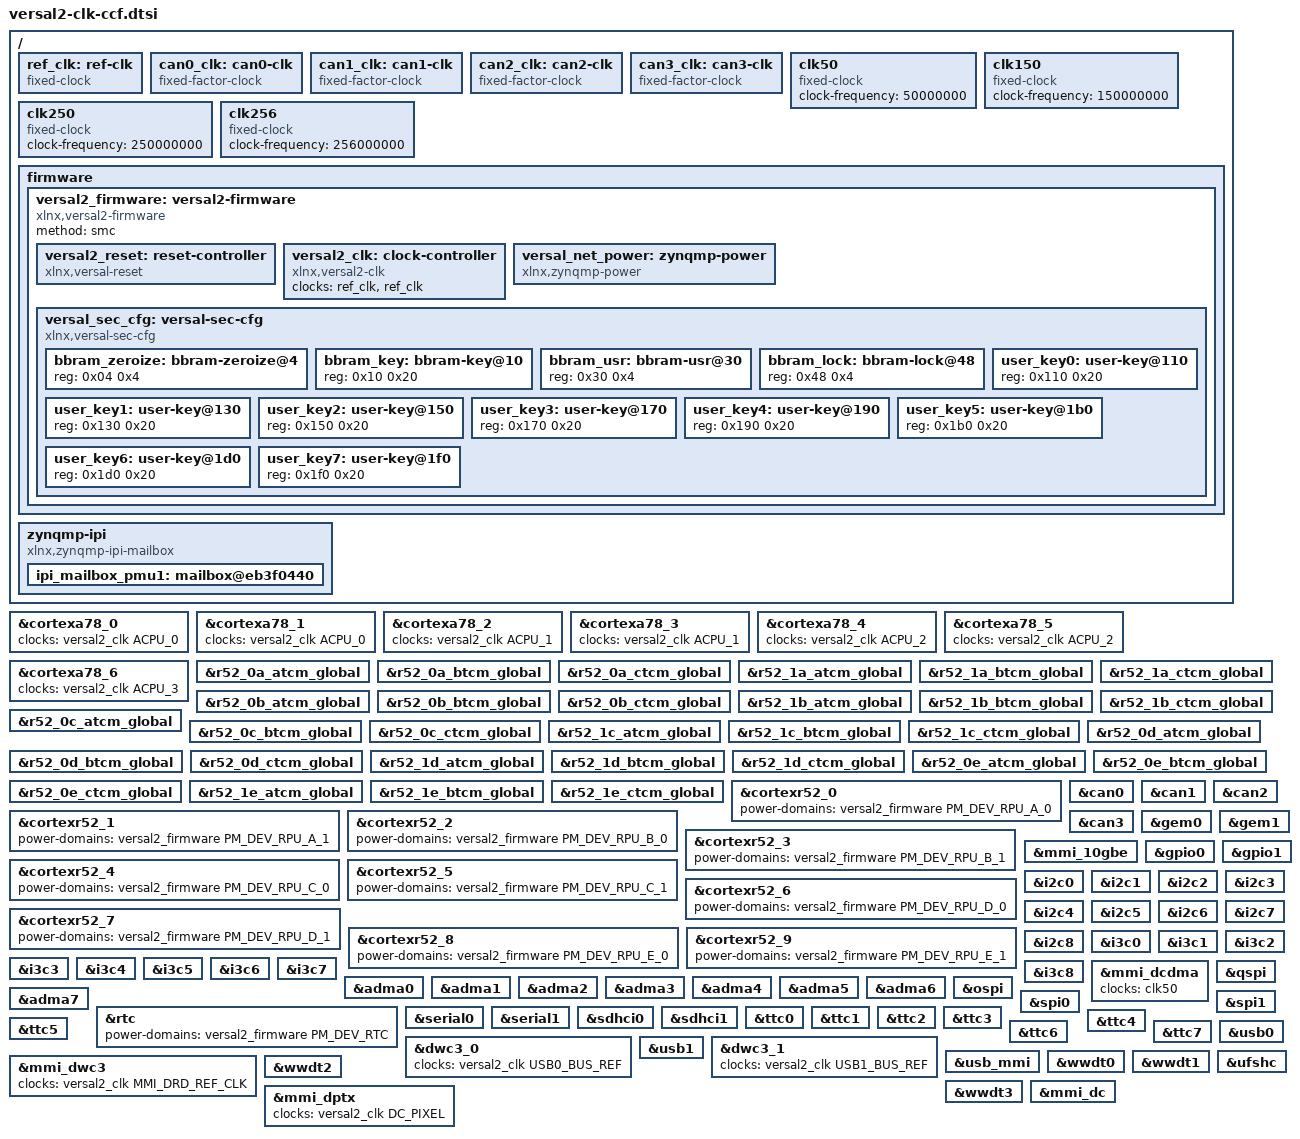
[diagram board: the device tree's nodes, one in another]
// SPDX-License-Identifier: GPL-2.0
/*
 * dts file for Xilinx Versal2 with PM
 *
 * Copyright (C) 2022, Xilinx, Inc.
 * Copyright (C) 2022 - 2025, Advanced Micro Devices, Inc.
 *
 * Michal Simek <michal.simek@amd.com>
 */

#include "include/dt-bindings/clock/xlnx-versal2-clk.h"
#include "include/dt-bindings/power/xlnx-versal2-power.h"
#include "include/dt-bindings/reset/xlnx-versal2-resets.h"

/ {
	ref_clk: ref-clk {
		bootph-all;
		compatible = "fixed-clock";
		#clock-cells = <0>;
		clock-frequency = <33333333>;
		clock-output-names = "ref_clk";
	};

	can0_clk: can0-clk {
		#clock-cells = <0>;
		compatible = "fixed-factor-clock";
		clocks = <&versal2_clk CAN0_REF_2X>;
		clock-div = <2>;
		clock-mult = <1>;
	};

	can1_clk: can1-clk {
		#clock-cells = <0>;
		compatible = "fixed-factor-clock";
		clocks = <&versal2_clk CAN1_REF_2X>;
		clock-div = <2>;
		clock-mult = <1>;
	};

	can2_clk: can2-clk {
		#clock-cells = <0>;
		compatible = "fixed-factor-clock";
		clocks = <&versal2_clk CAN2_REF_2X>;
		clock-div = <2>;
		clock-mult = <1>;
	};

	can3_clk: can3-clk {
		#clock-cells = <0>;
		compatible = "fixed-factor-clock";
		clocks = <&versal2_clk CAN3_REF_2X>;
		clock-div = <2>;
		clock-mult = <1>;
	};

	clk50: clk50 {
		compatible = "fixed-clock";
		#clock-cells = <0>;
		clock-frequency = <50000000>;
	};

	clk150: clk150 {
		compatible = "fixed-clock";
		#clock-cells = <0>;
		clock-frequency = <150000000>;
	};

	clk250: clk250 {
		compatible = "fixed-clock";
		#clock-cells = <0>;
		clock-frequency = <250000000>;
	};

	clk256: clk256 {
		compatible = "fixed-clock";
		#clock-cells = <0>;
		clock-frequency = <256000000>;
	};

	firmware {
		versal2_firmware: versal2-firmware {
			compatible = "xlnx,versal2-firmware";
			bootph-all;
			method = "smc";
			#power-domain-cells = <1>;

			versal2_reset: reset-controller {
				compatible = "xlnx,versal-reset";
				#reset-cells = <1>;
			};

			versal2_clk: clock-controller {
				#clock-cells = <1>;
				compatible = "xlnx,versal2-clk";
				bootph-all;
				clocks = <&ref_clk>, <&ref_clk>;
				clock-names = "ref", "pl_alt_ref";
			};

			versal_net_power: zynqmp-power { // NT Pending
				compatible = "xlnx,zynqmp-power";
				interrupt-parent = <&imux>;
				interrupts = <0 57 4>;
				mboxes = <&ipi_mailbox_pmu1 0>,
					 <&ipi_mailbox_pmu1 1>;
				mbox-names = "tx", "rx";
			};

			versal_sec_cfg: versal-sec-cfg { // NT Pending
				compatible = "xlnx,versal-sec-cfg";
				#address-cells = <1>;
				#size-cells = <1>;

				bbram_zeroize: bbram-zeroize@4 {
					reg = <0x04 0x4>;
				};

				bbram_key: bbram-key@10 {
					reg = <0x10 0x20>;
				};

				bbram_usr: bbram-usr@30 {
					reg = <0x30 0x4>;
				};

				bbram_lock: bbram-lock@48 {
					reg = <0x48 0x4>;
				};

				user_key0: user-key@110 {
					reg = <0x110 0x20>;
				};

				user_key1: user-key@130 {
					reg = <0x130 0x20>;
				};

				user_key2: user-key@150 {
					reg = <0x150 0x20>;
				};

				user_key3: user-key@170 {
					reg = <0x170 0x20>;
				};

				user_key4: user-key@190 {
					reg = <0x190 0x20>;
				};

				user_key5: user-key@1b0 {
					reg = <0x1b0 0x20>;
				};

				user_key6: user-key@1d0 {
					reg = <0x1d0 0x20>;
				};

				user_key7: user-key@1f0 {
					reg = <0x1f0 0x20>;
				};
			};
		};
	};

	zynqmp-ipi {
		compatible = "xlnx,zynqmp-ipi-mailbox";
		interrupt-parent = <&imux>;
		interrupts = <0 57 4>;
		xlnx,ipi-id = <2>;
		#address-cells = <2>;
		#size-cells = <2>;
		ranges;

		ipi_mailbox_pmu1: mailbox@eb3f0440 {
			reg = <0 0xeb3f0440 0 0x20>,
			      <0 0xeb3f0460 0 0x20>,
			      <0 0xeb3f0280 0 0x20>,
			      <0 0xeb3f02a0 0 0x20>;
			reg-names = "local_request_region", "local_response_region",
				    "remote_request_region", "remote_response_region";
			#mbox-cells = <1>;
			xlnx,ipi-id = <1>;
		};
	};
};

&cortexa78_0 {
	clocks = <&versal2_clk ACPU_0>;
};

&cortexa78_1 {
	clocks = <&versal2_clk ACPU_0>;
};

&cortexa78_2 {
	clocks = <&versal2_clk ACPU_1>;
};

&cortexa78_3 {
	clocks = <&versal2_clk ACPU_1>;
};

&cortexa78_4 {
	clocks = <&versal2_clk ACPU_2>;
};

&cortexa78_5 {
	clocks = <&versal2_clk ACPU_2>;
};

&cortexa78_6 {
	clocks = <&versal2_clk ACPU_3>;
};

&cortexa78_6 {
	clocks = <&versal2_clk ACPU_3>;
};

&r52_0a_atcm_global {
	power-domains = <&versal2_firmware PM_DEV_TCM_A_0A>;
};

&r52_0a_btcm_global {
	power-domains = <&versal2_firmware PM_DEV_TCM_A_0B>;
};

&r52_0a_ctcm_global {
	power-domains = <&versal2_firmware PM_DEV_TCM_A_0C>;
};

&r52_1a_atcm_global {
	power-domains = <&versal2_firmware PM_DEV_TCM_A_1A>;
};

&r52_1a_btcm_global {
	power-domains = <&versal2_firmware PM_DEV_TCM_A_1B>;
};

&r52_1a_ctcm_global {
	power-domains = <&versal2_firmware PM_DEV_TCM_A_1C>;
};

&r52_0b_atcm_global {
	power-domains = <&versal2_firmware PM_DEV_TCM_B_0A>;
};

&r52_0b_btcm_global {
	power-domains = <&versal2_firmware PM_DEV_TCM_B_0B>;
};

&r52_0b_ctcm_global {
	power-domains = <&versal2_firmware PM_DEV_TCM_B_0C>;
};

&r52_1b_atcm_global {
	power-domains = <&versal2_firmware PM_DEV_TCM_B_1A>;
};

&r52_1b_btcm_global {
	power-domains = <&versal2_firmware PM_DEV_TCM_B_1B>;
};

&r52_1b_ctcm_global {
	power-domains = <&versal2_firmware PM_DEV_TCM_B_1C>;
};

&r52_0c_atcm_global {
	power-domains = <&versal2_firmware PM_DEV_TCM_C_0A>;
};

&r52_0c_btcm_global {
	power-domains = <&versal2_firmware PM_DEV_TCM_C_0B>;
};

&r52_0c_ctcm_global {
	power-domains = <&versal2_firmware PM_DEV_TCM_C_0C>;
};

&r52_1c_atcm_global {
	power-domains = <&versal2_firmware PM_DEV_TCM_C_1A>;
};

&r52_1c_btcm_global {
	power-domains = <&versal2_firmware PM_DEV_TCM_C_1B>;
};

&r52_1c_ctcm_global {
	power-domains = <&versal2_firmware PM_DEV_TCM_C_1C>;
};

&r52_0d_atcm_global {
	power-domains = <&versal2_firmware PM_DEV_TCM_D_0A>;
};

&r52_0d_btcm_global {
	power-domains = <&versal2_firmware PM_DEV_TCM_D_0B>;
};

&r52_0d_ctcm_global {
	power-domains = <&versal2_firmware PM_DEV_TCM_D_0C>;
};

&r52_1d_atcm_global {
	power-domains = <&versal2_firmware PM_DEV_TCM_D_1A>;
};

&r52_1d_btcm_global {
	power-domains = <&versal2_firmware PM_DEV_TCM_D_1B>;
};

&r52_1d_ctcm_global {
	power-domains = <&versal2_firmware PM_DEV_TCM_D_1C>;
};

&r52_0e_atcm_global {
	power-domains = <&versal2_firmware PM_DEV_TCM_E_0A>;
};

&r52_0e_btcm_global {
	power-domains = <&versal2_firmware PM_DEV_TCM_E_0B>;
};

&r52_0e_ctcm_global {
	power-domains = <&versal2_firmware PM_DEV_TCM_E_0C>;
};

&r52_1e_atcm_global {
	power-domains = <&versal2_firmware PM_DEV_TCM_E_1A>;
};

&r52_1e_btcm_global {
	power-domains = <&versal2_firmware PM_DEV_TCM_E_1B>;
};

&r52_1e_ctcm_global {
	power-domains = <&versal2_firmware PM_DEV_TCM_E_1C>;
};

&cortexr52_0 {
	power-domains = <&versal2_firmware PM_DEV_RPU_A_0>;
};

&cortexr52_1 {
	power-domains = <&versal2_firmware PM_DEV_RPU_A_1>;
};

&cortexr52_2 {
	power-domains = <&versal2_firmware PM_DEV_RPU_B_0>;
};

&cortexr52_3 {
	power-domains = <&versal2_firmware PM_DEV_RPU_B_1>;
};

&cortexr52_4 {
	power-domains = <&versal2_firmware PM_DEV_RPU_C_0>;
};

&cortexr52_5 {
	power-domains = <&versal2_firmware PM_DEV_RPU_C_1>;
};

&cortexr52_6 {
	power-domains = <&versal2_firmware PM_DEV_RPU_D_0>;
};

&cortexr52_7 {
	power-domains = <&versal2_firmware PM_DEV_RPU_D_1>;
};


&cortexr52_8 {
	power-domains = <&versal2_firmware PM_DEV_RPU_E_0>;
};

&cortexr52_9 {
	power-domains = <&versal2_firmware PM_DEV_RPU_E_1>;
};

&can0 {
	clocks = <&can0_clk>, <&versal2_clk LPD_LSBUS>;
	power-domains = <&versal2_firmware PM_DEV_CAN_FD_0>;
};

&can1 {
	clocks = <&can1_clk>, <&versal2_clk LPD_LSBUS>;
	power-domains = <&versal2_firmware PM_DEV_CAN_FD_1>;
};

&can2 {
	clocks = <&can2_clk>, <&versal2_clk LPD_LSBUS>;
	power-domains = <&versal2_firmware PM_DEV_CAN_FD_2>;
};

&can3 {
	clocks = <&can3_clk>, <&versal2_clk LPD_LSBUS>;
	power-domains = <&versal2_firmware PM_DEV_CAN_FD_3>;
};

&gem0 {
	clocks = <&versal2_clk LPD_LSBUS>,
		 <&versal2_clk GEM0_REF>, <&versal2_clk GEM0_TX>,
		 <&versal2_clk GEM0_RX>, <&versal2_clk GEM_TSU>;
	power-domains = <&versal2_firmware PM_DEV_GEM_0>;
};

&gem1 {
	clocks = <&versal2_clk LPD_LSBUS>,
		 <&versal2_clk GEM1_REF>, <&versal2_clk GEM1_TX>,
		 <&versal2_clk GEM1_RX>, <&versal2_clk GEM_TSU>;
	power-domains = <&versal2_firmware PM_DEV_GEM_1>;
};

&mmi_10gbe {
	clocks = <&versal2_clk LPD_LSBUS>,
		<&versal2_clk MMI_GEM_HCLK>, <&clk150>,
		<&clk250>;
	power-domains = <&versal2_firmware PM_DEV_MMI_GEM>;
};

&gpio0 {
	clocks = <&versal2_clk LPD_LSBUS>;
	power-domains = <&versal2_firmware PM_DEV_GPIO>;
};

&gpio1 {
	clocks = <&versal2_clk PMC_LSBUS_REF>;
	power-domains = <&versal2_firmware PM_DEV_GPIO_PMC>;
};

&i2c0 {
	clocks = <&versal2_clk I3C0_REF>;
	power-domains = <&versal2_firmware PM_DEV_I2C_0>;
};

&i2c1 {
	clocks = <&versal2_clk I3C1_REF>;
	power-domains = <&versal2_firmware PM_DEV_I2C_1>;
};

&i2c2 {
	clocks = <&versal2_clk I3C2_REF>;
	power-domains = <&versal2_firmware PM_DEV_I2C_2>;
};

&i2c3 {
	clocks = <&versal2_clk I3C3_REF>;
	power-domains = <&versal2_firmware PM_DEV_I2C_3>;
};

&i2c4 {
	clocks = <&versal2_clk I3C4_REF>;
	power-domains = <&versal2_firmware PM_DEV_I2C_4>;
};

&i2c5 {
	clocks = <&versal2_clk I3C5_REF>;
	power-domains = <&versal2_firmware PM_DEV_I2C_5>;
};

&i2c6 {
	clocks = <&versal2_clk I3C6_REF>;
	power-domains = <&versal2_firmware PM_DEV_I2C_6>;
};

&i2c7 {
	clocks = <&versal2_clk I3C7_REF>;
	power-domains = <&versal2_firmware PM_DEV_I2C_7>;
};

&i2c8 {
	clocks = <&versal2_clk I2C_REF>;
	power-domains = <&versal2_firmware PM_DEV_I2C_PMC>;
};

&i3c0 {
	clocks = <&versal2_clk I3C0_REF>;
	power-domains = <&versal2_firmware PM_DEV_I2C_0>;
};

&i3c1 {
	clocks = <&versal2_clk I3C1_REF>;
	power-domains = <&versal2_firmware PM_DEV_I2C_1>;
};

&i3c2 {
	clocks = <&versal2_clk I3C2_REF>;
	power-domains = <&versal2_firmware PM_DEV_I2C_2>;
};

&i3c3 {
	clocks = <&versal2_clk I3C3_REF>;
	power-domains = <&versal2_firmware PM_DEV_I2C_3>;
};

&i3c4 {
	clocks = <&versal2_clk I3C4_REF>;
	power-domains = <&versal2_firmware PM_DEV_I2C_4>;
};

&i3c5 {
	clocks = <&versal2_clk I3C5_REF>;
	power-domains = <&versal2_firmware PM_DEV_I2C_5>;
};

&i3c6 {
	clocks = <&versal2_clk I3C6_REF>;
	power-domains = <&versal2_firmware PM_DEV_I2C_6>;
};

&i3c7 {
	clocks = <&versal2_clk I3C7_REF>;
	power-domains = <&versal2_firmware PM_DEV_I2C_7>;
};

&i3c8 {
	clocks = <&versal2_clk I2C_REF>;
	power-domains = <&versal2_firmware PM_DEV_I2C_PMC>;
};

&mmi_dcdma {
	clocks = <&ref_clk>;
};

&adma0 {
	clocks = <&versal2_clk ADMA>, <&versal2_clk LPD_LSBUS>;
	power-domains = <&versal2_firmware PM_DEV_ADMA_0>;
};

&adma1 {
	clocks = <&versal2_clk ADMA>, <&versal2_clk LPD_LSBUS>;
	power-domains = <&versal2_firmware PM_DEV_ADMA_1>;
};

&adma2 {
	clocks = <&versal2_clk ADMA>, <&versal2_clk LPD_LSBUS>;
	power-domains = <&versal2_firmware PM_DEV_ADMA_2>;
};

&adma3 {
	clocks = <&versal2_clk ADMA>, <&versal2_clk LPD_LSBUS>;
	power-domains = <&versal2_firmware PM_DEV_ADMA_3>;
};

&adma4 {
	clocks = <&versal2_clk ADMA>, <&versal2_clk LPD_LSBUS>;
	power-domains = <&versal2_firmware PM_DEV_ADMA_4>;
};

&adma5 {
	clocks = <&versal2_clk ADMA>, <&versal2_clk LPD_LSBUS>;
	power-domains = <&versal2_firmware PM_DEV_ADMA_5>;
};

&adma6 {
	clocks = <&versal2_clk ADMA>, <&versal2_clk LPD_LSBUS>;
	power-domains = <&versal2_firmware PM_DEV_ADMA_6>;
};

&adma7 {
	clocks = <&versal2_clk ADMA>, <&versal2_clk LPD_LSBUS>;
	power-domains = <&versal2_firmware PM_DEV_ADMA_7>;
};

&qspi {
	clocks = <&versal2_clk QSPI_REF>, <&versal2_clk LPD_LSBUS>;
	power-domains = <&versal2_firmware PM_DEV_QSPI>;
};

&ospi {
	clocks = <&versal2_clk OSPI_REF>;
	power-domains = <&versal2_firmware PM_DEV_OSPI>;
	resets = <&versal2_reset VERSAL_RST_OSPI>;
};

&rtc {
	power-domains = <&versal2_firmware PM_DEV_RTC>;
};

&serial0 {
	clocks = <&versal2_clk UART0_REF>, <&versal2_clk LPD_LSBUS>;
	power-domains = <&versal2_firmware PM_DEV_UART_0>;
};

&serial1 {
	clocks = <&versal2_clk UART1_REF>, <&versal2_clk LPD_LSBUS>;
	power-domains = <&versal2_firmware PM_DEV_UART_1>;
};

&sdhci0 {
	clocks = <&versal2_clk SDIO0_REF>, <&versal2_clk LPD_LSBUS>,
		<&versal2_clk SD_DLL_REF>;
	power-domains = <&versal2_firmware PM_DEV_SDIO_0>;
};

&sdhci1 {
	clocks = <&versal2_clk SDIO1_REF>, <&versal2_clk LPD_LSBUS>,
		<&versal2_clk SD_DLL_REF>;
	power-domains = <&versal2_firmware PM_DEV_SDIO_1>;
};

&spi0 {
	clocks = <&versal2_clk SPI0_REF>, <&versal2_clk LPD_LSBUS>;
	power-domains = <&versal2_firmware PM_DEV_SPI_0>;
};

&spi1 {
	clocks = <&versal2_clk SPI1_REF>, <&versal2_clk LPD_LSBUS>;
	power-domains = <&versal2_firmware PM_DEV_SPI_1>;
};

&ttc0 {
	clocks = <&versal2_clk TTC0>;
	power-domains = <&versal2_firmware PM_DEV_TTC_0>;
};

&ttc1 {
	clocks = <&versal2_clk TTC1>;
	power-domains = <&versal2_firmware PM_DEV_TTC_1>;
};

&ttc2 {
	clocks = <&versal2_clk TTC2>;
	power-domains = <&versal2_firmware PM_DEV_TTC_2>;
};

&ttc3 {
	clocks = <&versal2_clk TTC3>;
	power-domains = <&versal2_firmware PM_DEV_TTC_3>;
};

&ttc4 {
	clocks = <&versal2_clk TTC4>;
	power-domains = <&versal2_firmware PM_DEV_TTC_4>;
};

&ttc5 {
	clocks = <&versal2_clk TTC5>;
	power-domains = <&versal2_firmware PM_DEV_TTC_5>;
};

&ttc6 {
	clocks = <&versal2_clk TTC6>;
	power-domains = <&versal2_firmware PM_DEV_TTC_6>;
};

&ttc7 {
	clocks = <&versal2_clk TTC7>;
	power-domains = <&versal2_firmware PM_DEV_TTC_7>;
};

&usb0 {
	clocks = <&versal2_clk USB0_BUS_REF>, <&versal2_clk USB0_BUS_REF>;
	power-domains = <&versal2_firmware PM_DEV_USB_0>;
	resets = <&versal2_reset VERSAL_RST_USB_0>;
};

&dwc3_0 {
	clocks = <&versal2_clk USB0_BUS_REF>;
};

&usb1 {
	clocks = <&versal2_clk USB1_BUS_REF>, <&versal2_clk USB1_BUS_REF>;
	power-domains = <&versal2_firmware PM_DEV_USB_1>;
	resets = <&versal2_reset VERSAL_RST_USB_1>;
};

&dwc3_1 {
	clocks = <&versal2_clk USB1_BUS_REF>;
};

&usb_mmi {
	clocks = <&clk256>, <&versal2_clk MMI_DRD_REF_CLK>;
	resets = <&versal2_reset VERSAL_RST_UDH_DRD>;
	power-domains = <&versal2_firmware PM_DEV_MMI_USB_DRD>;
};

&mmi_dwc3 {
	clocks = <&versal2_clk MMI_DRD_REF_CLK>;
};

&mmi_dcdma {
	clocks = <&clk50>;
};

&wwdt0 {
	clocks = <&versal2_clk FPD_WWDT0>;
	power-domains = <&versal2_firmware PM_DEV_FPD_SWDT_0>;
};

&wwdt1 {
	clocks = <&versal2_clk FPD_WWDT1>;
	power-domains = <&versal2_firmware PM_DEV_FPD_SWDT_1>;
};

&wwdt2 {
	clocks = <&versal2_clk FPD_WWDT2>;
	power-domains = <&versal2_firmware PM_DEV_FPD_SWDT_2>;
};

&wwdt3 {
	clocks = <&versal2_clk FPD_WWDT3>;
	power-domains = <&versal2_firmware PM_DEV_FPD_SWDT_3>;
};

&ufshc {
	clocks = <&versal2_clk UFS_REF>;
	power-domains = <&versal2_firmware PM_DEV_UFS>;
	resets = <&versal2_reset VERSAL_RST_UFS>, <&versal2_reset VERSAL_RST_UFS_PHY>;
};

&mmi_dc {
	clocks = <&versal2_clk DC_PIXEL>;
	resets = <&versal2_reset VERSAL_RST_DC>;
};

&mmi_dptx {
	clocks = <&versal2_clk DC_PIXEL>;
};
